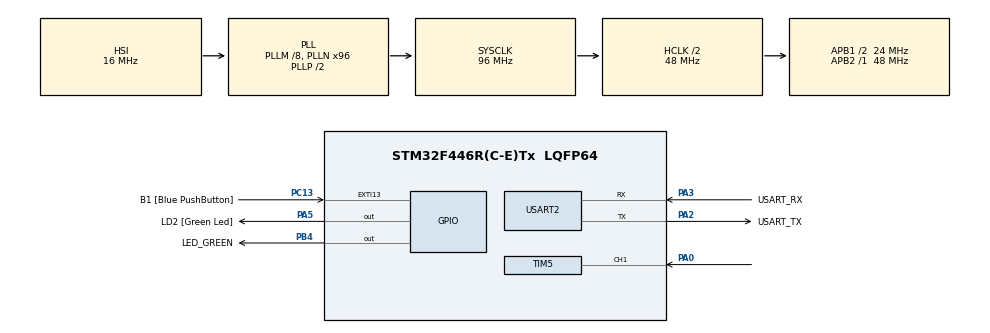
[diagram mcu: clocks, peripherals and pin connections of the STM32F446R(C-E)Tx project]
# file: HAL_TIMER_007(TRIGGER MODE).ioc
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Mcu.Family=STM32F4
Mcu.Name=STM32F446R(C-E)Tx
Mcu.Package=LQFP64
NVIC.PriorityGroup=NVIC_PRIORITYGROUP_0
NVIC.TIM5_IRQn=true\:0\:0\:false\:false\:true\:true\:true
PA0-WKUP.Signal=S_TIM5_CH1
PA13.GPIO_Label=TMS
PA13.Mode=Serial_Wire
PA13.Signal=SYS_JTMS-SWDIO
PA14.GPIO_Label=TCK
PA14.Mode=Serial_Wire
PA14.Signal=SYS_JTCK-SWCLK
PA2.GPIO_Label=USART_TX
PA2.Mode=Asynchronous
PA2.Signal=USART2_TX
PA3.GPIO_Label=USART_RX
PA3.Mode=Asynchronous
PA3.Signal=USART2_RX
PA5.GPIO_Label=LD2 [Green Led]
PA5.Signal=GPIO_Output
PB3.GPIO_Label=SWO
PB3.Signal=SYS_JTDO-SWO
PB4.GPIO_Label=LED_GREEN
PB4.Signal=GPIO_Output
PC13.GPIO_Label=B1 [Blue PushButton]
PC13.GPIO_ModeDefaultEXTI=GPIO_MODE_IT_FALLING
PC13.Signal=GPXTI13
PC14-OSC32_IN.Mode=LSE-External-Oscillator
PC14-OSC32_IN.Signal=RCC_OSC32_IN
PC15-OSC32_OUT.Mode=LSE-External-Oscillator
PC15-OSC32_OUT.Signal=RCC_OSC32_OUT
PH0-OSC_IN.Mode=HSE-External-Oscillator
PH0-OSC_IN.Signal=RCC_OSC_IN
PH1-OSC_OUT.Mode=HSE-External-Oscillator
PH1-OSC_OUT.Signal=RCC_OSC_OUT
ProjectManager.HeapSize=0x200
ProjectManager.StackSize=0x400
ProjectManager.TargetToolchain=MDK-ARM V5
RCC.48MHZClocksFreq_Value=84000000
RCC.AHBCLKDivider=RCC_SYSCLK_DIV2
RCC.AHBFreq_Value=48000000
RCC.APB1CLKDivider=RCC_HCLK_DIV2
RCC.APB1Freq_Value=24000000
RCC.APB1TimFreq_Value=48000000
RCC.APB2Freq_Value=48000000
RCC.APB2TimFreq_Value=48000000
RCC.CortexFreq_Value=48000000
RCC.FLatency-AdvancedSettings=FLASH_LATENCY_1
RCC.HCLKFreq_Value=48000000
RCC.HSE_VALUE=8000000
RCC.HSI_VALUE=16000000
RCC.PLLM=8
RCC.PLLN=96
RCC.SYSCLKFreq_VALUE=96000000
RCC.SYSCLKSource=RCC_SYSCLKSOURCE_PLLCLK
RCC.USBFreq_Value=96000000
RCC.VCOOutputFreq_Value=192000000
SH.S_TIM5_CH1.0=TIM5_CH1,TriggerSource_TI1FP1
TIM5.Period=499
TIM5.Prescaler=47999
TIM5.Slave_TriggerFilter=15
USART2.VirtualMode=VM_ASYNC
VP_TIM5_VS_ClockSourceINT.Mode=Internal
VP_TIM5_VS_ControllerModeTrigger.Mode=Trigger Mode
board=NUCLEO-F446RE

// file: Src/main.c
/* USER CODE BEGIN Header */
/**
  ******************************************************************************
  * @file           : main.c
  * @brief          : Main program body
  ******************************************************************************
  * @attention
  *
  * <h2><center>&copy; Copyright (c) 2020 STMicroelectronics.
  * All rights reserved.</center></h2>
  *
  * This software component is licensed by ST under BSD 3-Clause license,
  * the "License"; You may not use this file except in compliance with the
  * License. You may obtain a copy of the License at:
  *                        opensource.org/licenses/BSD-3-Clause
  *
  ******************************************************************************
  */
/* USER CODE END Header */

#include "main.h"

TIM_HandleTypeDef htim5;

UART_HandleTypeDef huart2;

/* USER CODE BEGIN PV */
	uint32_t count_TIM5=0;
/* USER CODE END PV */

void SystemClock_Config(void);
static void MX_GPIO_Init(void);
static void MX_USART2_UART_Init(void);
static void MX_TIM5_Init(void);
/* USER CODE BEGIN PFP */

 void HAL_TIM_PeriodElapsedCallback(TIM_HandleTypeDef *htim)		// interrupt olustugunda yürütülecek fonksiyon
 {
	 if(htim->Instance==TIM5)
	 {
		 	HAL_GPIO_TogglePin(LED_GREEN_GPIO_Port,LED_GREEN_Pin);
	 }
 }

/* USER CODE END PFP */

int main(void)
{

  /* MCU Configuration--------------------------------------------------------*/

  /* Reset of all peripherals, Initializes the Flash interface and the Systick. */
  HAL_Init();

  /* Configure the system clock */
  SystemClock_Config();

  /* Initialize all configured peripherals */
  MX_GPIO_Init();
  MX_USART2_UART_Init();
  MX_TIM5_Init();
  /* USER CODE BEGIN 2 */

	__HAL_TIM_CLEAR_FLAG(&htim5,TIM_FLAG_UPDATE);
  /* USER CODE END 2 */

  /* Infinite loop */
  /* USER CODE BEGIN WHILE */
  while (1)
  {

		count_TIM5= __HAL_TIM_GetCounter(&htim5);
		while(__HAL_TIM_GET_FLAG(&htim5,TIM_FLAG_TRIGGER)!=RESET)		// Biz tetikleme verdigimiz andan itibaren saymaya basliyor trigger mode
		{
			HAL_GPIO_TogglePin(LD2_GPIO_Port,LD2_Pin);
			__HAL_TIM_ENABLE_IT(&htim5,TIM_FLAG_UPDATE);			// 	Yukarida timer a start vermedigimiz için kesme olusmuyor. Bu sekilde kesme bayragini aktif ediyoruz.
			__HAL_TIM_CLEAR_FLAG(&htim5,TIM_FLAG_TRIGGER);
		}
    /* USER CODE END WHILE */

  }
}

void SystemClock_Config(void)
{
  RCC_OscInitTypeDef RCC_OscInitStruct = {0};
  RCC_ClkInitTypeDef RCC_ClkInitStruct = {0};

  /** Configure the main internal regulator output voltage
  */
  __HAL_RCC_PWR_CLK_ENABLE();
  __HAL_PWR_VOLTAGESCALING_CONFIG(PWR_REGULATOR_VOLTAGE_SCALE3);
  /** Initializes the CPU, AHB and APB busses clocks
  */
  RCC_OscInitStruct.OscillatorType = RCC_OSCILLATORTYPE_HSI;
  RCC_OscInitStruct.HSIState = RCC_HSI_ON;
  RCC_OscInitStruct.HSICalibrationValue = RCC_HSICALIBRATION_DEFAULT;
  RCC_OscInitStruct.PLL.PLLState = RCC_PLL_ON;
  RCC_OscInitStruct.PLL.PLLSource = RCC_PLLSOURCE_HSI;
  RCC_OscInitStruct.PLL.PLLM = 8;
  RCC_OscInitStruct.PLL.PLLN = 96;
  RCC_OscInitStruct.PLL.PLLP = RCC_PLLP_DIV2;
  RCC_OscInitStruct.PLL.PLLQ = 2;
  RCC_OscInitStruct.PLL.PLLR = 2;
  if (HAL_RCC_OscConfig(&RCC_OscInitStruct) != HAL_OK)
  {
    Error_Handler();
  }
  /** Initializes the CPU, AHB and APB busses clocks
  */
  RCC_ClkInitStruct.ClockType = RCC_CLOCKTYPE_HCLK|RCC_CLOCKTYPE_SYSCLK
                              |RCC_CLOCKTYPE_PCLK1|RCC_CLOCKTYPE_PCLK2;
  RCC_ClkInitStruct.SYSCLKSource = RCC_SYSCLKSOURCE_PLLCLK;
  RCC_ClkInitStruct.AHBCLKDivider = RCC_SYSCLK_DIV2;
  RCC_ClkInitStruct.APB1CLKDivider = RCC_HCLK_DIV2;
  RCC_ClkInitStruct.APB2CLKDivider = RCC_HCLK_DIV1;

  if (HAL_RCC_ClockConfig(&RCC_ClkInitStruct, FLASH_LATENCY_1) != HAL_OK)
  {
    Error_Handler();
  }
}

static void MX_TIM5_Init(void)
{

  TIM_ClockConfigTypeDef sClockSourceConfig = {0};
  TIM_SlaveConfigTypeDef sSlaveConfig = {0};
  TIM_MasterConfigTypeDef sMasterConfig = {0};

  htim5.Instance = TIM5;
  htim5.Init.Prescaler = 47999;
  htim5.Init.CounterMode = TIM_COUNTERMODE_UP;
  htim5.Init.Period = 499;
  htim5.Init.ClockDivision = TIM_CLOCKDIVISION_DIV1;
  htim5.Init.AutoReloadPreload = TIM_AUTORELOAD_PRELOAD_DISABLE;
  if (HAL_TIM_Base_Init(&htim5) != HAL_OK)
  {
    Error_Handler();
  }
  sClockSourceConfig.ClockSource = TIM_CLOCKSOURCE_INTERNAL;
  if (HAL_TIM_ConfigClockSource(&htim5, &sClockSourceConfig) != HAL_OK)
  {
    Error_Handler();
  }
  sSlaveConfig.SlaveMode = TIM_SLAVEMODE_TRIGGER;
  sSlaveConfig.InputTrigger = TIM_TS_TI1FP1;
  sSlaveConfig.TriggerPolarity = TIM_TRIGGERPOLARITY_RISING;
  sSlaveConfig.TriggerFilter = 15;
  if (HAL_TIM_SlaveConfigSynchro(&htim5, &sSlaveConfig) != HAL_OK)
  {
    Error_Handler();
  }
  sMasterConfig.MasterOutputTrigger = TIM_TRGO_RESET;
  sMasterConfig.MasterSlaveMode = TIM_MASTERSLAVEMODE_DISABLE;
  if (HAL_TIMEx_MasterConfigSynchronization(&htim5, &sMasterConfig) != HAL_OK)
  {
    Error_Handler();
  }

}

static void MX_USART2_UART_Init(void)
{

  huart2.Instance = USART2;
  huart2.Init.BaudRate = 115200;
  huart2.Init.WordLength = UART_WORDLENGTH_8B;
  huart2.Init.StopBits = UART_STOPBITS_1;
  huart2.Init.Parity = UART_PARITY_NONE;
  huart2.Init.Mode = UART_MODE_TX_RX;
  huart2.Init.HwFlowCtl = UART_HWCONTROL_NONE;
  huart2.Init.OverSampling = UART_OVERSAMPLING_16;
  if (HAL_UART_Init(&huart2) != HAL_OK)
  {
    Error_Handler();
  }

}

static void MX_GPIO_Init(void)
{
  GPIO_InitTypeDef GPIO_InitStruct = {0};

  /* GPIO Ports Clock Enable */
  __HAL_RCC_GPIOC_CLK_ENABLE();
  __HAL_RCC_GPIOH_CLK_ENABLE();
  __HAL_RCC_GPIOA_CLK_ENABLE();
  __HAL_RCC_GPIOB_CLK_ENABLE();

  /*Configure GPIO pin Output Level */
  HAL_GPIO_WritePin(LD2_GPIO_Port, LD2_Pin, GPIO_PIN_RESET);

  /*Configure GPIO pin Output Level */
  HAL_GPIO_WritePin(LED_GREEN_GPIO_Port, LED_GREEN_Pin, GPIO_PIN_RESET);

  /*Configure GPIO pin : B1_Pin */
  GPIO_InitStruct.Pin = B1_Pin;
  GPIO_InitStruct.Mode = GPIO_MODE_IT_FALLING;
  GPIO_InitStruct.Pull = GPIO_NOPULL;
  HAL_GPIO_Init(B1_GPIO_Port, &GPIO_InitStruct);

  /*Configure GPIO pin : LD2_Pin */
  GPIO_InitStruct.Pin = LD2_Pin;
  GPIO_InitStruct.Mode = GPIO_MODE_OUTPUT_PP;
  GPIO_InitStruct.Pull = GPIO_NOPULL;
  GPIO_InitStruct.Speed = GPIO_SPEED_FREQ_LOW;
  HAL_GPIO_Init(LD2_GPIO_Port, &GPIO_InitStruct);

  /*Configure GPIO pin : LED_GREEN_Pin */
  GPIO_InitStruct.Pin = LED_GREEN_Pin;
  GPIO_InitStruct.Mode = GPIO_MODE_OUTPUT_PP;
  GPIO_InitStruct.Pull = GPIO_NOPULL;
  GPIO_InitStruct.Speed = GPIO_SPEED_FREQ_LOW;
  HAL_GPIO_Init(LED_GREEN_GPIO_Port, &GPIO_InitStruct);

}

void Error_Handler(void)
{
}

/************************ (C) COPYRIGHT STMicroelectronics *****END OF FILE****/
